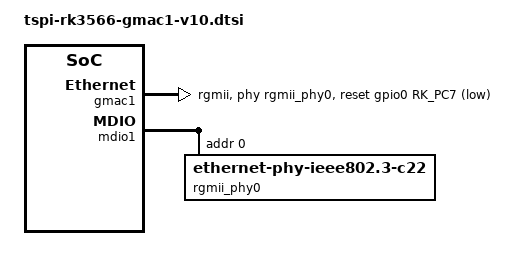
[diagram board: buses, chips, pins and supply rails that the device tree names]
// SPDX-License-Identifier: (GPL-2.0+ OR MIT)
/*
 * Copyright (c) 2020 Rockchip Electronics Co., Ltd.
 *
 */

&gmac1 {
	phy-mode = "rgmii";
	clock_in_out = "output";

	snps,reset-gpio = <&gpio0 RK_PC7 GPIO_ACTIVE_LOW>;
	snps,reset-active-low;
	/* Reset time is 20ms, 100ms for rtl8211f */
	snps,reset-delays-us = <0 20000 100000>;

	assigned-clocks = <&cru SCLK_GMAC1_RX_TX>, <&cru SCLK_GMAC1>;
	assigned-clock-parents = <&cru SCLK_GMAC1_RGMII_SPEED>, <&cru CLK_MAC1_2TOP>;
	assigned-clock-rates = <0>, <125000000>;

	pinctrl-names = "default";
	pinctrl-0 = <&gmac1m1_miim
		     &gmac1m1_tx_bus2
		     &gmac1m1_rx_bus2
		     &gmac1m1_rgmii_clk
		     &gmac1m1_rgmii_bus>;

	tx_delay = <0x4f>;
	rx_delay = <0x25>;

	phy-handle = <&rgmii_phy0>;
	status = "okay";
};

&mdio1 {
	rgmii_phy0: phy@0 {
		compatible = "ethernet-phy-ieee802.3-c22";
		reg = <0x0>;
	};
};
